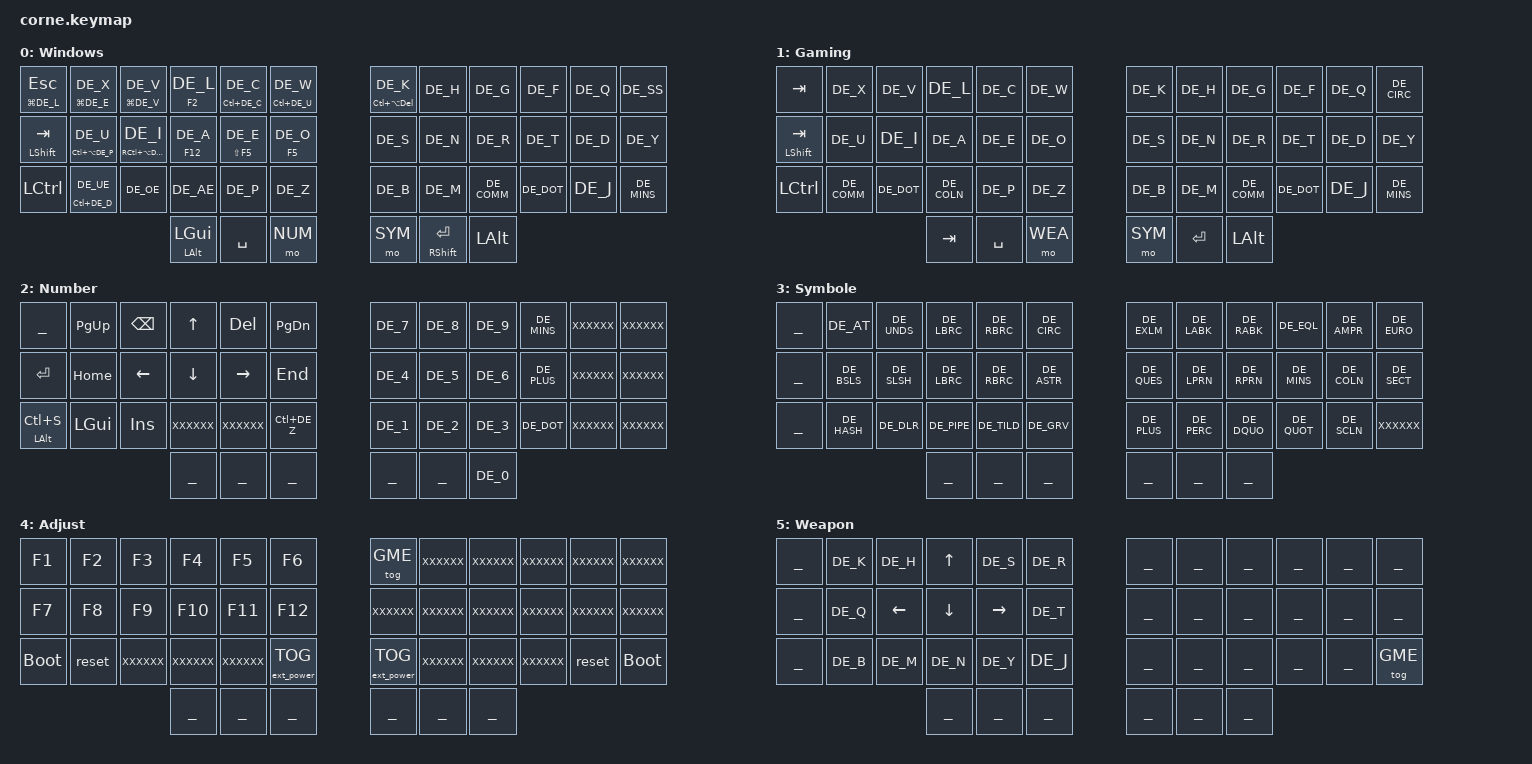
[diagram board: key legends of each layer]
 /*
 * Copyright (c) 2020 The ZMK Contributors
 *
 * SPDX-License-Identifier: MIT
 * NEO 2
 */


#include <behaviors.dtsi>
#include <dt-bindings/zmk/keys.h>
#include <dt-bindings/zmk/bt.h>
#include <dt-bindings/zmk/ext_power.h>
#include "CustomFunction/define_keys.dtsi"
#include "CustomFunction/taps.keymap"
//#include "secrets.keymap"

#define WIN 0
#define GME 1
#define NUM 2
#define SYM 3
#define ADJ 4
#define WEA 5 


/ {

   // Activate ADJUST layer by pressing raise and lower
    conditional_layers {
        compatible = "zmk,conditional-layers";
        adjust_layer {
            if-layers = <SYM NUM>;
            then-layer = <ADJ>;
        };
    };

    keymap {
        compatible = "zmk,keymap";
        win_layer {
            label = "Windows";
            bindings = <
// ╭─────────────────────┬─────────────────────┬─────────────────────┬─────────────────────┬─────────────────────┬─────────────────────╮                                             ╭─────────────────────┬─────────────────────┬─────────────────────┬─────────────────────┬─────────────────────┬─────────────────────╮
      &bhm LG(DE_L) ESC    &bhm LG(DE_E) DE_X     &bhm LG(DE_V) DE_V      &bhm F2 DE_L        &bhm LC(DE_C) DE_C    &bhm LC(DE_U) DE_W                                                &bhm LC(LA(DEL)) DE_K       &kp DE_H              &kp DE_G              &kp DE_F              &kp DE_Q              &kp DE_SS
// ├─────────────────────┼─────────────────────┼─────────────────────┼─────────────────────┼─────────────────────┼─────────────────────┤                                             ├─────────────────────┼─────────────────────┼─────────────────────┼─────────────────────┼─────────────────────┼─────────────────────┤
       &mt LSHIFT TAB     &bhm LC(LA(DE_P)) DE_U &bhm RC(LA(DE_R)) DE_I &bhm F12 DE_A          &bhm LS(F5) DE_E       &bhm F5 DE_O                                                          &kp DE_S              &kp DE_N              &kp DE_R              &kp DE_T              &kp DE_D              &kp DE_Y
// ├─────────────────────┼─────────────────────┼─────────────────────┼─────────────────────┼─────────────────────┼─────────────────────┤                                             ├─────────────────────┼─────────────────────┼─────────────────────┼─────────────────────┼─────────────────────┤─────────────────────┤
        &kp LCTRL          &bhm LC(DE_D) DE_UE        &kp DE_OE             &kp DE_AE             &kp DE_P               &kp DE_Z                                                           &kp DE_B              &kp DE_M             &kp DE_COMM           &kp DE_DOT             &kp DE_J             &kp DE_MINS
// ╰─────────────────────┴─────────────────────┴─────────────────────┴─────────────────────┼─────────────────────┼─────────────────────┤─────────────────────╮ ╭─────────────────────┼─────────────────────┼─────────────────────┼─────────────────────┴─────────────────────┴─────────────────────┴─────────────────────╯
                                                                                                &mt LALT LGUI           &kp SPACE              &mo NUM                  &mo SYM           &mt RSHIFT RET          &kp LALT
//                                                                                         ╰─────────────────────┴─────────────────────┴─────────────────────╯ ╰─────────────────────┴─────────────────────┴─────────────────────╯
            >;
            sensor-bindings = <&inc_dec_kp C_VOL_UP C_VOL_DN &inc_dec_kp PG_UP PG_DN>;
        };
// -------------------------------------------------------------------------------------------------------------------------------------------------------------------------------------------------------------------------------------------------
        gme_layer {
            label = "Gaming";
            bindings = <
// ╭─────────────────────┬─────────────────────┬─────────────────────┬─────────────────────┬─────────────────────┬─────────────────────╮                                             ╭─────────────────────┬─────────────────────┬─────────────────────┬─────────────────────┬─────────────────────┬─────────────────────╮
           &kp TAB               &kp DE_X            &kp DE_V               &kp DE_L               &kp DE_C             &kp DE_W                                                            &kp DE_K              &kp DE_H              &kp DE_G              &kp DE_F              &kp DE_Q             &kp DE_CIRC
// ├─────────────────────┼─────────────────────┼─────────────────────┼─────────────────────┼─────────────────────┼─────────────────────┤                                             ├─────────────────────┼─────────────────────┼─────────────────────┼─────────────────────┼─────────────────────┼─────────────────────┤
        &mt LSHIFT TAB           &kp DE_U            &kp DE_I               &kp DE_A               &kp DE_E             &kp DE_O                                                            &kp DE_S              &kp DE_N              &kp DE_R              &kp DE_T              &kp DE_D              &kp DE_Y
// ├─────────────────────┼─────────────────────┼─────────────────────┼─────────────────────┼─────────────────────┼─────────────────────┤                                             ├─────────────────────┼─────────────────────┼─────────────────────┼─────────────────────┼─────────────────────┼─────────────────────┤
          &kp LCTRL             &kp DE_COMM         &kp DE_DOT            &kp DE_COLN              &kp DE_P             &kp DE_Z                                                            &kp DE_B              &kp DE_M            &kp DE_COMM             &kp DE_DOT             &kp DE_J            &kp DE_MINS
// ╰─────────────────────┴─────────────────────┴─────────────────────┴─────────────────────┼─────────────────────┼─────────────────────┤─────────────────────╮ ╭─────────────────────┼─────────────────────┼─────────────────────┼─────────────────────┴─────────────────────┴─────────────────────┴─────────────────────╯
                                                                                                   &kp TAB              &kp SPACE              &mo WEA                 &mo SYM               &kp RET              &kp LALT
//                                                                                         ╰─────────────────────┴─────────────────────┴─────────────────────╯ ╰─────────────────────┴─────────────────────┴─────────────────────╯
            >;
            sensor-bindings = <&inc_dec_kp C_VOL_UP C_VOL_DN &inc_dec_kp PG_UP PG_DN>;
        };
// -------------------------------------------------------------------------------------------------------------------------------------------------------------------------------------------------------------------------------------------------
        num_layer {
            label = "Number";
            bindings = <

// ╭─────────────────────┬─────────────────────┬─────────────────────┬─────────────────────┬─────────────────────┬─────────────────────╮                                             ╭─────────────────────┬─────────────────────┬─────────────────────┬─────────────────────┬─────────────────────┬─────────────────────╮
           ______              &kp PAGE_UP            &kp BSPC                &kp UP               &kp DEL            &kp PAGE_DOWN                                                          &kp DE_7              &kp DE_8              &kp DE_9             &kp DE_MINS             XXXXXX                XXXXXX
// ├─────────────────────┼─────────────────────┼─────────────────────┼─────────────────────┼─────────────────────┼─────────────────────┤                                             ├─────────────────────┼─────────────────────┼─────────────────────┼─────────────────────┼─────────────────────┼─────────────────────┤
           &kp RET              &kp HOME              &kp LEFT               &kp DOWN             &kp RIGHT             &kp END                                                              &kp DE_4              &kp DE_5              &kp DE_6             &kp DE_PLUS             XXXXXX                XXXXXX
// ├─────────────────────┼─────────────────────┼─────────────────────┼─────────────────────┼─────────────────────┼─────────────────────┤                                             ├─────────────────────┼─────────────────────┼─────────────────────┼─────────────────────┼─────────────────────┼─────────────────────┤
        &mt LALT LC(S)          &kp LGUI              &kp INS                XXXXXX                XXXXXX              &kp LC(DE_Z)                                                          &kp DE_1              &kp DE_2              &kp DE_3              &kp DE_DOT             XXXXXX                XXXXXX
// ╰─────────────────────┴─────────────────────┴─────────────────────┴─────────────────────┼─────────────────────┼─────────────────────┤─────────────────────╮ ╭─────────────────────┼─────────────────────┼─────────────────────┼─────────────────────┴─────────────────────┴─────────────────────┴─────────────────────╯
                                                                                                   ______                 ______                ______                  ______                ______               &kp DE_0
//                                                                                         ╰─────────────────────┴─────────────────────┴─────────────────────╯ ╰─────────────────────┴─────────────────────┴─────────────────────╯
            >;
            sensor-bindings = <&inc_dec_kp C_VOL_UP C_VOL_DN &inc_dec_kp PG_UP PG_DN>;
        };
// -------------------------------------------------------------------------------------------------------------------------------------------------------------------------------------------------------------------------------------------------
        sym_layer {
            label = "Symbole";
            bindings = <
// ╭─────────────────────┬─────────────────────┬─────────────────────┬─────────────────────┬─────────────────────┬─────────────────────╮                                             ╭─────────────────────┬─────────────────────┬─────────────────────┬─────────────────────┬─────────────────────┬─────────────────────╮
            ______               &kp DE_AT           &kp DE_UNDS           &kp DE_LBRC            &kp DE_RBRC          &kp DE_CIRC                                                         &kp DE_EXLM           &kp DE_LABK           &kp DE_RABK           &kp DE_EQL            &kp DE_AMPR           &kp DE_EURO
// ├─────────────────────┼─────────────────────┼─────────────────────┼─────────────────────┼─────────────────────┼─────────────────────┤                                             ├─────────────────────┼─────────────────────┼─────────────────────┼─────────────────────┼─────────────────────┼─────────────────────┤
            ______             &kp DE_BSLS           &kp DE_SLSH           &kp DE_LBRC            &kp DE_RBRC          &kp DE_ASTR                                                         &kp DE_QUES           &kp DE_LPRN           &kp DE_RPRN           &kp DE_MINS           &kp DE_COLN           &kp DE_SECT
// ├─────────────────────┼─────────────────────┼─────────────────────┼─────────────────────┼─────────────────────┼─────────────────────┤                                             ├─────────────────────┼─────────────────────┼─────────────────────┼─────────────────────┼─────────────────────┼─────────────────────┤
            ______             &kp DE_HASH           &kp DE_DLR            &kp DE_PIPE            &kp DE_TILD          &kp DE_GRV                                                          &kp DE_PLUS           &kp DE_PERC           &kp DE_DQUO           &kp DE_QUOT           &kp DE_SCLN             XXXXXX
// ╰─────────────────────┴─────────────────────┴─────────────────────┴─────────────────────┼─────────────────────┼─────────────────────┤─────────────────────╮ ╭─────────────────────┼─────────────────────┼─────────────────────┼─────────────────────┴─────────────────────┴─────────────────────┴─────────────────────╯
                                                                                                    ______               ______                ______                  ______                ______                ______
//                                                                                         ╰─────────────────────┴─────────────────────┴─────────────────────╯ ╰─────────────────────┴─────────────────────┴─────────────────────╯
            >;
            sensor-bindings = <&inc_dec_cp C_VOL_UP C_VOL_DN &inc_dec_kp PG_UP PG_DN>;
        };
// -------------------------------------------------------------------------------------------------------------------------------------------------------------------------------------------------------------------------------------------------
        adj_layer {
            label = "Adjust";
            bindings = <
// ╭─────────────────────┬─────────────────────┬─────────────────────┬─────────────────────┬─────────────────────┬─────────────────────╮                                             ╭─────────────────────┬─────────────────────┬─────────────────────┬─────────────────────┬─────────────────────┬─────────────────────╮
           &kp F1                &kp F2                &kp F3                &kp F4                &kp F5                &kp F6                                                             &tog GME                XXXXXX                XXXXXX                XXXXXX                XXXXXX                XXXXXX
// ├─────────────────────┼─────────────────────┼─────────────────────┼─────────────────────┼─────────────────────┼─────────────────────┤                                             ├─────────────────────┼─────────────────────┼─────────────────────┼─────────────────────┼─────────────────────┼─────────────────────┤
           &kp F7                &kp F8                &kp F9                &kp F10               &kp F11               &kp F12                                                             XXXXXX                 XXXXXX                XXXXXX                XXXXXX                XXXXXX                XXXXXX
// ├─────────────────────┼─────────────────────┼─────────────────────┼─────────────────────┼─────────────────────┼─────────────────────┤                                             ├─────────────────────┼─────────────────────┼─────────────────────┼─────────────────────┼─────────────────────┼─────────────────────┤
         &bootloader             &reset                XXXXXX                XXXXXX                XXXXXX           &ext_power EP_TOG                                                   &ext_power EP_TOG           XXXXXX                XXXXXX                XXXXXX                &reset              &bootloader
// ╰─────────────────────┴─────────────────────┴─────────────────────┴─────────────────────┼─────────────────────┼─────────────────────┤─────────────────────╮ ╭─────────────────────┼─────────────────────┼─────────────────────┼─────────────────────┴─────────────────────┴─────────────────────┴─────────────────────╯
                                                                                                   ______                 ______                ______                 ______                ______                 ______
//                                                                                         ╰─────────────────────┴─────────────────────┴─────────────────────╯ ╰─────────────────────┴─────────────────────┴─────────────────────╯
            >;
            sensor-bindings = <&inc_dec_kp C_VOL_UP C_VOL_DN &inc_dec_kp PG_UP PG_DN>;
        };
// -------------------------------------------------------------------------------------------------------------------------------------------------------------------------------------------------------------------------------------------------
        wea_layer {
            label = "Weapon";
            bindings = <
// ╭─────────────────────┬─────────────────────┬─────────────────────┬─────────────────────┬─────────────────────┬─────────────────────╮                                             ╭─────────────────────┬─────────────────────┬─────────────────────┬─────────────────────┬─────────────────────┬─────────────────────╮
            ______              &kp DE_K              &kp DE_H               &kp UP               &kp DE_S              &kp DE_R                                                             ______                ______                ______                ______                 ______               ______
// ├─────────────────────┼─────────────────────┼─────────────────────┼─────────────────────┼─────────────────────┼─────────────────────┤                                             ├─────────────────────┼─────────────────────┼─────────────────────┼─────────────────────┼─────────────────────┼─────────────────────┤
            ______              &kp DE_Q              &kp LEFT              &kp DOWN             &kp RIGHT              &kp DE_T                                                             ______                ______                ______                ______                 ______               ______
// ├─────────────────────┼─────────────────────┼─────────────────────┼─────────────────────┼─────────────────────┼─────────────────────┤                                             ├─────────────────────┼─────────────────────┼─────────────────────┼─────────────────────┼─────────────────────┼─────────────────────┤
            ______              &kp DE_B              &kp DE_M              &kp DE_N              &kp DE_Y              &kp DE_J                                                             ______                ______                ______                ______                 ______               &tog GME
// ╰─────────────────────┴─────────────────────┴─────────────────────┴─────────────────────┼─────────────────────┼─────────────────────┤─────────────────────╮ ╭─────────────────────┼─────────────────────┼─────────────────────┼─────────────────────┴─────────────────────┴─────────────────────┴─────────────────────╯
                                                                                                   ______                 ______                ______                  ______               ______                ______
//                                                                                         ╰─────────────────────┴─────────────────────┴─────────────────────╯ ╰─────────────────────┴─────────────────────┴─────────────────────╯
            >;
            sensor-bindings = <&inc_dec_kp C_VOL_UP C_VOL_DN &inc_dec_kp PG_UP PG_DN>;
        };
     };
};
